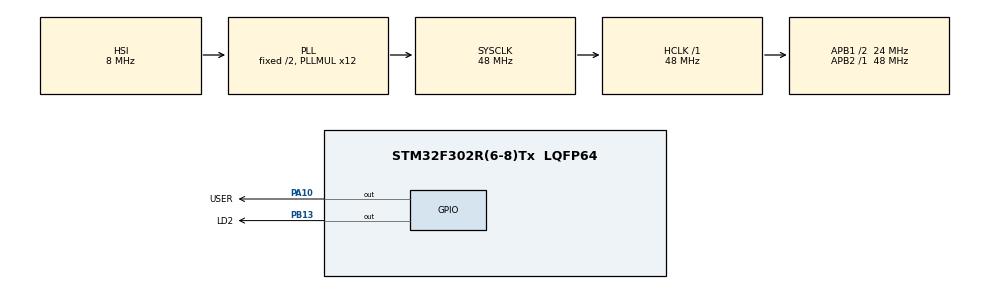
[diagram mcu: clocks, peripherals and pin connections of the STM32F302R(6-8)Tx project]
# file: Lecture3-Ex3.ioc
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Mcu.Family=STM32F3
Mcu.Name=STM32F302R(6-8)Tx
Mcu.Package=LQFP64
NVIC.PriorityGroup=NVIC_PRIORITYGROUP_0
NVIC.TIM1_UP_TIM16_IRQn=true\:0\:0\:false\:false\:true\:true\:true\:true
PA10.GPIO_Label=USER
PA10.Signal=GPIO_Output
PB13.GPIO_Label=LD2
PB13.Signal=GPIO_Output
PC14\ -\ OSC32_IN.Mode=LSE-External-Oscillator
PC14\ -\ OSC32_IN.Signal=RCC_OSC32_IN
PC15\ -\ OSC32_OUT.Mode=LSE-External-Oscillator
PC15\ -\ OSC32_OUT.Signal=RCC_OSC32_OUT
PF0-OSC_IN.Mode=HSE-External-Clock-Source
PF0-OSC_IN.Signal=RCC_OSC_IN
ProjectManager.HeapSize=0x200
ProjectManager.StackSize=0x400
ProjectManager.TargetToolchain=STM32CubeIDE
RCC.AHBFreq_Value=48000000
RCC.APB1CLKDivider=RCC_HCLK_DIV2
RCC.APB1Freq_Value=24000000
RCC.APB1TimFreq_Value=48000000
RCC.APB2Freq_Value=48000000
RCC.APB2TimFreq_Value=48000000
RCC.CortexFreq_Value=48000000
RCC.HCLKFreq_Value=48000000
RCC.HSE_VALUE=8000000
RCC.HSI_VALUE=8000000
RCC.PLLM=8
RCC.PLLMUL=RCC_PLL_MUL12
RCC.PLLN=336
RCC.PLLP=RCC_PLLP_DIV4
RCC.PLLQ=7
RCC.RCC_PLLsource_Clock_Source_FROM_HSE=RCC_HSE_PREDIV_DIV2
RCC.SYSCLKFreq_VALUE=48000000
RCC.SYSCLKSourceVirtual=RCC_SYSCLKSOURCE_PLLCLK
RCC.USBFreq_Value=48000000
TIM16.Period=2400
TIM16.Prescaler=10000
VP_TIM16_VS_ClockSourceINT.Mode=Enable_Timer
board=NUCLEO-F302R8

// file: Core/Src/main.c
/* USER CODE BEGIN Header */
/**
  ******************************************************************************
  * @file           : main.c
  * @brief          : Main program body
  ******************************************************************************
  * @attention
  *
  * Copyright (c) 2026 STMicroelectronics.
  * All rights reserved.
  *
  * This software is licensed under terms that can be found in the LICENSE file
  * in the root directory of this software component.
  * If no LICENSE file comes with this software, it is provided AS-IS.
  *
  ******************************************************************************
  */
/* USER CODE END Header */
#include "main.h"
#include "tim.h"
#include "gpio.h"

void SystemClock_Config(void);

int main(void)
{

  /* MCU Configuration--------------------------------------------------------*/

  /* Reset of all peripherals, Initializes the Flash interface and the Systick. */
  HAL_Init();

  /* Configure the system clock */
  SystemClock_Config();

  /* Initialize all configured peripherals */
  MX_GPIO_Init();
  MX_TIM16_Init();
  /* USER CODE BEGIN 2 */
  HAL_TIM_Base_Start_IT(&htim16);
  /* USER CODE END 2 */

  /* Infinite loop */
  while (1)
  {

  }
}

void SystemClock_Config(void)
{
  RCC_OscInitTypeDef RCC_OscInitStruct = {0};
  RCC_ClkInitTypeDef RCC_ClkInitStruct = {0};
  RCC_PeriphCLKInitTypeDef PeriphClkInit = {0};

  /** Initializes the RCC Oscillators according to the specified parameters
  * in the RCC_OscInitTypeDef structure.
  */
  RCC_OscInitStruct.OscillatorType = RCC_OSCILLATORTYPE_HSI;
  RCC_OscInitStruct.HSIState = RCC_HSI_ON;
  RCC_OscInitStruct.HSICalibrationValue = RCC_HSICALIBRATION_DEFAULT;
  RCC_OscInitStruct.PLL.PLLState = RCC_PLL_ON;
  RCC_OscInitStruct.PLL.PLLSource = RCC_PLLSOURCE_HSI;
  RCC_OscInitStruct.PLL.PLLMUL = RCC_PLL_MUL12;
  if (HAL_RCC_OscConfig(&RCC_OscInitStruct) != HAL_OK)
  {
    Error_Handler();
  }

  /** Initializes the CPU, AHB and APB buses clocks
  */
  RCC_ClkInitStruct.ClockType = RCC_CLOCKTYPE_HCLK|RCC_CLOCKTYPE_SYSCLK
                              |RCC_CLOCKTYPE_PCLK1|RCC_CLOCKTYPE_PCLK2;
  RCC_ClkInitStruct.SYSCLKSource = RCC_SYSCLKSOURCE_PLLCLK;
  RCC_ClkInitStruct.AHBCLKDivider = RCC_SYSCLK_DIV1;
  RCC_ClkInitStruct.APB1CLKDivider = RCC_HCLK_DIV2;
  RCC_ClkInitStruct.APB2CLKDivider = RCC_HCLK_DIV1;

  if (HAL_RCC_ClockConfig(&RCC_ClkInitStruct, FLASH_LATENCY_1) != HAL_OK)
  {
    Error_Handler();
  }
  PeriphClkInit.PeriphClockSelection = RCC_PERIPHCLK_TIM16;
  PeriphClkInit.Tim16ClockSelection = RCC_TIM16CLK_HCLK;
  if (HAL_RCCEx_PeriphCLKConfig(&PeriphClkInit) != HAL_OK)
  {
    Error_Handler();
  }
}

/* USER CODE BEGIN 4 */
void HAL_TIM_PeriodElapsedCallback(TIM_HandleTypeDef *htim)
{
	HAL_GPIO_TogglePin(USER_GPIO_Port, USER_Pin);
	HAL_GPIO_TogglePin(LD2_GPIO_Port, LD2_Pin);
}
/* USER CODE END 4 */

void Error_Handler(void)
{
  __disable_irq();
  while (1)
  {
  }
}
